# max32660 register map
Vendor: Maxim-Integrated; Series: ARMCM4; File version: 1.0
MAX32660 Tiny, Ultra-Low-Power ARM Cortex-M4 Processor with FPU-Based Microcontroller with 256KB Flash and 96KB SRAM.
CPU: CM4 r2p1, little endian, MPU, FPU, 3 interrupt priority bits
Registers are 32-bit, read-write, reset 0x0 unless marked. A register's access mark holds for its fields unless they carry their own. Offsets are from the block's base; lines under a group give offsets from that group; [hi:lo] are bit positions; {n}, {i} and the like mark numbered series; 'fields as' and 'values as' point back to an identical list; <NAME> marks a mode.

## Memory map
0x40000000 GCR size 0x400 — Global Control Registers.
0x40000400 SIR size 0x400 — System Initialization Registers.
0x40000800 FCR size 0x400 — Function Control.
0x40003000 WDT0 size 0x400 — Watchdog Timer 0
0x40006000 RTC size 0x400 — Real Time Clock and Alarm.
0x40006800 PWRSEQ size 0x800 — Power Sequencer / Low Power Control Register.
0x40008000 GPIO0 size 0x1000 — Individual I/O for each GPIO
0x40010000 TMR0 size 0x1000 — Low-Power Configurable Timer
0x40011000 TMR1 size 0x1000 — Low-Power Configurable Timer 1
0x40012000 TMR2 size 0x1000 — Low-Power Configurable Timer 2
0x40019000 SPIMSS size 0x1000 — Serial Peripheral Interface.
0x4001D000 I2C0 size 0x1000 — Inter-Integrated Circuit.
0x4001E000 I2C1 size 0x1000 — Inter-Integrated Circuit. 1
0x40028000 DMA size 0x1000 — DMA Controller Fully programmable, chaining capable DMA channels.
0x40029000 FLC size 0x1000 — Flash Memory Control.
0x4002A000 ICC0 size 0x1000 — Instruction Cache Controller Registers
0x40042000 UART0 size 0x1000 — UART
0x40043000 UART1 size 0x1000
0x40046000 SPI0 size 0x1000 — SPI peripheral.

## Interrupts
1 WDT0
3 RTC — RTC interrupt.
5 TMR (TMR0)
6 TMR1 — TMR1 IRQ
7 TMR2 — TMR2 IRQ
13 I2C0 — I2C0 IRQ
14 UART0 — UART0 IRQ
15 UART1 — UART1 IRQ
16 SPI0
23 Flash_Controller (FLC) — Flash Controller interrupt.
24 GPIO0 — GPIO0 interrupt.
28 DMA0 (DMA)
29 DMA1 (DMA)
30 DMA2 (DMA)
31 DMA3 (DMA)
36 I2C1 — I2C1 IRQ

## FCR — Function Control.
Base 0x40000800
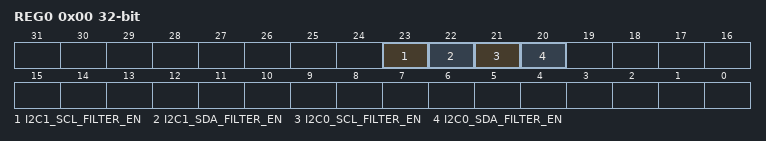
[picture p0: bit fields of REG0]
0x00 REG0 — Register 0.
  [all] fields
    0=dis (Filter disabled.); 1=en (Filter enabled.)
  [23] I2C1_SCL_FILTER_EN — I2C1 SCL Filter Enable
  [22] I2C1_SDA_FILTER_EN — I2C1 SDA Filter Enable
  [21] I2C0_SCL_FILTER_EN — I2C0 SCL Filter Enable
  [20] I2C0_SDA_FILTER_EN — I2C0 SDA Filter Enable

## FLC — Flash Memory Control.
Base 0x40029000; register names take the prefix FLC_
0x00 ADDR — Flash Write Address.
  [31:0] ADDR — Address for next operation.
0x04 CLKDIV reset 0x64 — Flash Clock Divide. The clock (PLL0) is divided by this value to generate a 1 MHz clock for Flash controller.
  [7:0] CLKDIV — Flash Clock Divide. The clock is divided by this value to generate a 1MHz clock for flash controller.
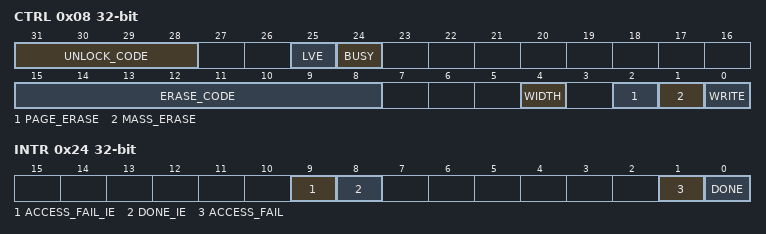
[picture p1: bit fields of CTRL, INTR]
0x08 CTRL — Flash Control Register.
  [31:28] UNLOCK_CODE — Flash Unlock. The correct unlock code must be written to these four bits before any Flash write or erase operation is allowed.
    2=unlocked (Flash Unlocked.); 3=locked (Flash Locked.)
  [25] LVE — Low Voltage enable.
  [24] BUSY ro — Flash Pending. When Flash operation is in progress (busy), Flash reads and writes will fail. When PEND is set, write to all Flash registers, with exception of the Flash interrupt register, are ignored.
    0=idle; 1=busy
  [15:8] ERASE_CODE — Erase Code. The ERASE_CODE must be set up property before erase operation can be initiated. These bits are automatically cleared after the operation is complete.
    0=nop (No operation.); 85=erasePage (Enable Page Erase.); 170=eraseAll (Enable Mass Erase. The debug port must be enabled.)
  [4] WIDTH — Data Width. This bits selects write data width.
    0=size128 (128-bit.); 1=size32 (32-bit.)
  [2] PAGE_ERASE — Page Erase. This bit is automatically cleared after the operation.
    0=complete (No operation/complete.); 1=Start operation
  [1] MASS_ERASE — Mass Erase. This bit is automatically cleared after the operation.
    0=complete (No operation/complete.); 1=Start operation
  [0] WRITE — Write. This bit is automatically cleared after the operation.
    0=complete (No operation/complete.); 1=Start operation
0x24 INTR — Flash Interrupt Register.
  [9] ACCESS_FAIL_IE — Flash Done Interrupt Enable.
    0=disable; 1=enable
  [8] DONE_IE — Flash Done Interrupt Enable.
    0=disable; 1=enable
  [1] ACCESS_FAIL — Flash Access Fail. This bit is set when an attempt is made to write the flash while the flash is busy or the flash is locked. This bit can only be set to 1 by hardware.
    0=noError (No Failure.); 1=error (Failure occurs.)
  [0] DONE — Flash Done Interrupt. This bit is set to 1 upon Flash write or erase completion.
    0=inactive (No interrupt is pending.); 1=pending (An interrupt is pending.)
{0x30+4i} DATA[{i}] (i=0..3) — Flash Write Data.
  [31:0] DATA — Data next operation.
0x40 ACTRL wo — Access Control Register. Writing the ACTRL register with the following values in the order shown, allows read and write access to the system and user Information block: pflc-actrl = 0x3a7f5ca3; pflc-actrl = 0xa1e34f20; pflc-actrl = 0x9608b2c1. When unlocked, a write of any word will disable access to system and user information block. Readback of this register is always zero.
  [31:0] ACTRL — Access control.
